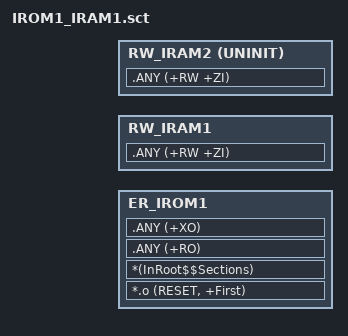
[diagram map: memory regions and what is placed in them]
#! armcc -E

; *************************************************************
; *** Scatter-Loading Description File generated by YF ***
; *************************************************************
; the header file must be in the same folder as the sct file
#include "project_debug.h"


LR_IROM1 IROM1_START_ADDR IROM1_SIZE              ; load region size_region
{  
	ER_IROM1 IROM1_START_ADDR IROM1_SIZE          ; load address = execution address
	{
		*.o (RESET, +First)
		*(InRoot$$Sections)
		.ANY (+RO)
		.ANY (+XO)
	}
	RW_IRAM1 IRAM1_START_ADDR IRAM1_SIZE          ; RW data
	{
		.ANY (+RW +ZI)
	}
	RW_IRAM2 IRAM2_START_ADDR UNINIT IRAM2_SIZE   ; RW data
	{
		.ANY (+RW +ZI)
	}
}

